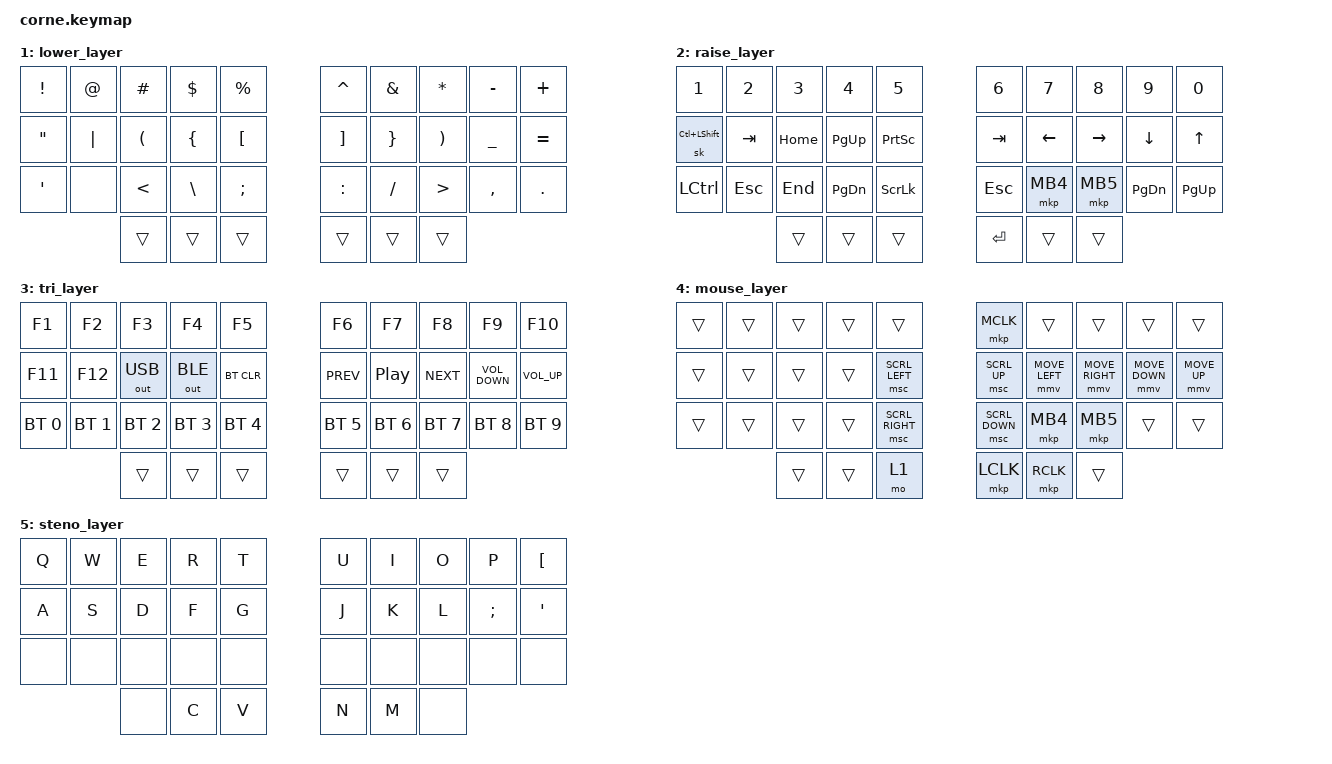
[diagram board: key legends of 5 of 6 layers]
/*
 * Copyright (c) 2020 The ZMK Contributors
 *
 * SPDX-License-Identifier: MIT
 */
#include <behaviors.dtsi> // I don't know what this does
#include <dt-bindings/zmk/keys.h> // This extends the options for the keymap bindings
#include <dt-bindings/zmk/outputs.h> //This allows you to toggle between Bluetooth and USB
#include <dt-bindings/zmk/bt.h> // This extends the functions of Bluetooth
#include <dt-bindings/zmk/mouse.h> // This enables mouse controls
#include <dt-bindings/zmk/pointing.h> // This also apparently activates "pointer device" control 

// Home row mods macro * This uses the HRM feature
#define HRML(k1, k2, k3, k4) &ht LALT k1  &ht LCTRL k2  &ht LGUI k3  &ht LSHFT k4
#define HRMR(k1, k2, k3, k4) &ht RSHFT k1  &ht RGUI k2  &ht RCTRL k3  &ht RALT k4
//Layers
        //Base Layer
        #define BASE 0 
        //Punctuation
        #define LOWER 1
        //Navigation
        #define RAISE 2
        // Bluetooth & Audio management 
        #define TRI 3
        // Mouse emulation
        #define MOUSE 4

#define ZMK_POINTING_DEFAULT_MOVE_VAL 1500  // default: 600 This changes the MAX mouse move velocities
#define ZMK_POINTING_DEFAULT_SCRL_VAL 20    // default: 10  This changes the MAX mouse move scroll

&mmv { // This controls the "base" movement speed & acceleration of "mouse move" function
    x-input-code = <INPUT_REL_X>;
    y-input-code = <INPUT_REL_Y>;
    time-to-max-speed-ms = <400>; // Default: 
    acceleration-exponent = <1>; // This is the exponent value for movement Default: 1 uniform speed 0, Uniform acceleration 1, linear acceleration 2
};
&msc { // This controls the "base" movement speed & acceleration of "Mouse Scroll" function
    x-input-code = <INPUT_REL_HWHEEL>;
    y-input-code = <INPUT_REL_WHEEL>;
    time-to-max-speed-ms = <300>;
    acceleration-exponent = <0>;
};

&mt {
};   

/ {
        chosen {
        zmk,matrix-transform = &five_column_transform;
        };
        conditional_layers { // This is a feature that allows you to make layers active as long as you hold them
            compatible = "zmk,conditional-layers";
            tri_layer {
                if-layers = <LOWER RAISE>;
                then-layer = <TRI>;
            };
        };  
       combos {// This allows key combinations perform other functions
            compatible = "zmk,combos";
                Combo_shift {
                        timeout-ms = <50>;
                        key-positions = <32 33>;
                        bindings = <&sk LSHFT>;
                        layers = < 0 1 >;
                };

        };
        behaviors {  
                ht: hold_tap {
                        label = "hold_tap";
                        compatible = "zmk,behavior-hold-tap";
                        #binding-cells = <2>;
                        flavor = "tap-preferred";
                        tapping-term-ms = <220>;
                        quick-tap-ms = <150>;
                        global-quick-tap;
                        bindings = <&kp>, <&kp>;
                };
                
                backspacenter: mod_del {
                        compatible = "zmk,behavior-mod-morph";
                        #binding-cells = <0>;
                        bindings = <&kp BSPC>, <&kp RET>;
                        mods = <(MOD_LSFT|MOD_RSFT)>;
                        keep-mods = <(MOD_LSFT)>;
                };
                spacedelete: grave_escape {
                        compatible = "zmk,behavior-mod-morph";
                        #binding-cells = <0>;
                        bindings = <&kp SPACE>, <&kp DEL>;
                        mods = <(MOD_LALT|MOD_RALT)>;
                        keep-mods = <(MOD_RALT)>;
                };

        };
        
        keymap {
                compatible = "zmk,keymap";
        default_layer {
                         bindings = <
                // ╭──────────┬──────────┬──────────┬──────────┬──────────╮       ╭──────────┬──────────┬──────────┬──────────┬──────────╮
                // |  Q       |  W       |  D       |  F       |  /       |       |  J       |  U       |  K       |  Y       |  '       |
                     &kp Q      &kp W      &kp D      &kp F      &kp FSLH           &kp J      &kp U      &kp K      &kp Y      &kp SQT
                // ├──────────┼──────────┼──────────┼──────────┼──────────┤       ├──────────┼──────────┼──────────┼──────────┼──────────┤
                // |  A, ALT  |  S, CTRL |  E, GUI  | T, SHIFT |  L       |       |  H       | N, SHIFT |  R, GUI  |  I, CTRL | O, ALT   |
                     HRML(A,    S,         E,         T)         &kp L              &kp H    HRMR(N,      R,         I,         O)   
                // ├──────────┼──────────┼──────────┼──────────┼──────────┤       ├──────────┼──────────┼──────────┼──────────┼──────────┤
                // |  G       |  X       |  C       |  V       |  Z       |       |  B       |  M       |  P       |  ,       |  .       |
                     &kp G      &kp X      &kp C      &kp V      &kp Z              &kp B      &kp M      &kp P      &kp COMMA  &kp DOT 
                // ╰──────────┴──────────┼──────────┼──────────┼──────────┤       ├──────────┴──────────┴──────────┼──────────┴──────────╯
                //                       |  Mouse   |          |          |       |          |          |          |
                                           &mo 4      &mo 2    &spacedelete      &backspacenter  &mo 1    &mo 2
                //                       ╰──────────┴──────────┴──────────╯       ╰──────────┴──────────┴──────────╯
                        >;
                };
        lower_layer {
                        bindings = <
                // ╭──────────┬──────────┬──────────┬──────────┬──────────╮       ╭──────────┬──────────┬──────────┬──────────┬──────────╮
                // |  !       |  @       |  #       |  $       |  %       |       |  ^       |  &       |  *       |  -       |  +       |
                     &kp EXCL   &kp AT     &kp HASH   &kp DLLR   &kp PRCNT          &kp CARET  &kp AMPS   &kp STAR   &kp MINUS  &kp PLUS   
                // ├──────────┼──────────┼──────────┼──────────┼──────────┤       ├──────────┼──────────┼──────────┼──────────┼──────────┤
                // |  "       |  "|"     |  (       | {        |  [       |       |  ]       |  }       |  )       |  _       |  =       |
                     &kp DQT    &kp PIPE   &kp LPAR  &kp LBRC   &kp LBKT            &kp RBKT   &kp RBRC   &kp RPAR   &kp UNDER  &kp EQUAL  
                // ├──────────┼──────────┼──────────┼──────────┼──────────┤       ├──────────┼──────────┼──────────┼──────────┼──────────┤
                // |  '       |          |  <       |  \       |  :       |       |  :       |  /       |  >       |  ,       |  .       |
                     &kp SQT    &none      &kp LT     &kp BSLH   &kp SEMI           &kp COLON  &kp FSLH   &kp GT     &kp COMMA  &kp DOT 
                // ╰──────────┴──────────┼──────────┼──────────┼──────────┤       ├──────────┴──────────┴──────────┼──────────┼──────────╯
                //                       |          |          |          |       |          |          |          |
                                            &trans     &trans     &trans             &trans     &trans     &trans
                //                       ╰──────────┴──────────┴──────────╯       ╰──────────┴──────────┴──────────╯
                        >;
                };
        raise_layer {
                        bindings = <
                // ╭──────────┬──────────┬──────────┬──────────┬──────────╮       ╭──────────┬──────────┬──────────┬──────────┬──────────╮
                // |  1       |  2       |  3       |  4       |  5       |       |  6       |  7       |  8       |  9       |  0       |
                      &kp N1     &kp N2     &kp N3     &kp N4     &kp N5             &kp N6     &kp N7     &kp N8     &kp N9     &kp N0 
                // ├──────────┼──────────┼──────────┼──────────┼──────────┤       ├──────────┼──────────┼──────────┼──────────┼──────────┤
                // | CTL+SHFT |  TAB     |  HOME    |  PGUP    | SCENSHOT |       |  TAB     |  left    |  right   |  DWN     |  UP      |
                &sk LC(LSHFT)   &kp TAB    &kp HOME   &kp PG_UP  &kp PSCRN          &kp TAB    &kp LEFT   &kp RIGHT  &kp DOWN   &kp UP  
                // ├──────────┼──────────┼──────────┼──────────┼──────────┤       ├──────────┼──────────┼──────────┼──────────┼──────────┤
                // |  CTRL    |  ESC     |  END     |  PGDN    |  SLCK    |       |  ESC     | Mouse 1  | Mouse 2  |PAGE DOWN | PAGE UP  |
                     &kp LCTRL  &kp ESC    &kp END    &kp PG_DN  &kp SLCK           &kp ESC    &mkp MB4   &mkp MB5 &kp PG_DN   &kp PG_UP  
                // ╰──────────┴──────────┼──────────┼──────────┼──────────┤       ├──────────┴──────────┴──────────┼──────────┴──────────╯
                //                       |          |          |          |       |  Enter   |          |          |
                                            &trans     &trans     &trans            &kp RET    &trans     &trans
                //                       ╰──────────┴──────────┴──────────╯       ╰──────────┴──────────┴──────────╯
                        >;
                };
                
        tri_layer {
                        bindings = < 
                // ╭──────────┬──────────┬──────────┬──────────┬──────────╮       ╭──────────┬──────────┬──────────┬──────────┬──────────╮
                // |  F1      |  F2      |  F3      |  F4      |  F5      |       |  F6      |  F7      |  F8      |  F9      |  F10     |
                     &kp F1     &kp F2     &kp F3     &kp F4     &kp F5              &kp F6    &kp F7     &kp F8     &kp F9     &kp F10  
                // ├──────────┼──────────┼──────────┼──────────┼──────────┤       ├──────────┼──────────┼──────────┼──────────┼──────────┤
                // |  F11     |  F12     | OUT USB  |  Out Bt  | BT Clear |       |   PREV   |   PLAY   |   NEXT   |   VO-    |   VO+    |
                     &kp F11    &kp F12  &out OUT_USB &out OUT_BLE &bt BT_CLR       &kp C_PREV &kp C_PP &kp C_NEXT &kp C_VOLUME_DOWN &kp C_VOL_UP 
                // ├──────────┼──────────┼──────────┼──────────┼──────────┤       ├──────────┼──────────┼──────────┼──────────┼──────────┤
                // | BT DEV 1 |BT DEV 2  | BT DEV 3 | BT DEV 4 | BT DEV 5 |       | BT DEV 6 | BT DEV 7 | BT DEV 8 | BT DEV 9 | BT DEV 10|
                &bt BT_SEL 0 &bt BT_SEL 1 &bt BT_SEL 2 &bt BT_SEL 3 &bt BT_SEL 4 &bt BT_SEL 5 &bt BT_SEL 6 &bt BT_SEL 7 &bt BT_SEL 8 &bt BT_SEL 9     
                // ╰──────────┴──────────┼──────────┼──────────┼──────────┤       ├──────────┴──────────┴──────────┼──────────┴──────────╯
                //                       |          |          |          |       |          |          |          |
                                           &trans     &trans     &trans             &trans     &trans     &trans
                //                       ╰──────────┴──────────┴──────────╯       ╰──────────┴──────────┴──────────╯
                        >;
                };
        mouse_layer { 
                        bindings = <
                // ╭──────────┬──────────┬──────────┬──────────┬──────────╮       ╭──────────┬──────────┬──────────┬──────────┬──────────╮
                // |          |          |          |          |          |       |  MIDDLE  |          |          |          |          |
                     &trans     &trans     &trans     &trans     &trans             &mkp MCLK  &trans     &trans     &trans     &trans
                // ├──────────┼──────────┼──────────┼──────────┼──────────┤       ├──────────┼──────────┼──────────┼──────────┼──────────┤
                // |  DOUBLE  |   HALF   |          |          |Scrl Left |       |Scrl UP   |  M Left  | M Right  | M Down   |  M Up    |
                     &trans     &trans    &trans      &trans     &msc SCRL_LEFT    &msc SCRL_UP &mmv MOVE_LEFT &mmv MOVE_RIGHT &mmv MOVE_DOWN &mmv MOVE_UP 
                // ├──────────┼──────────┼──────────┼──────────┼──────────┤       ├──────────┼──────────┼──────────┼──────────┼──────────┤
                // |          |          |          |          |Scrl Right|       |Scrl Down | Mouse 1  | Mouse 2  |          |          |
                     &trans     &trans     &trans     &trans     &msc SCRL_RIGHT  &msc SCRL_DOWN &mkp MB4 &mkp MB5   &trans     &trans 
                // ╰──────────┴──────────┼──────────┼──────────┼──────────┤       ├──────────┼──────────┼──────────┼──────────┴──────────╯
                //                       |          |          |  base    |       |Left Clk  |Right Clk |          |
                                           &trans     &trans     &mo 1            &mkp LCLK  &mkp RCLK     &trans 
                //                       ╰──────────┴──────────┴──────────╯       ╰──────────┴──────────┴──────────╯
                        >;
                };
        steno_layer {
                        bindings = <
                // ╭──────────┬──────────┬──────────┬──────────┬──────────╮       ╭──────────┬──────────┬──────────┬──────────┬──────────╮
                // |  Q, S    |  W, T    |  E, P    |  R, H    |  T, *    |       |  U, F    |  I, P    |  O, L    |  P, T    |  [, D    | 
                     &kp Q      &kp W      &kp E      &kp R      &kp T              &kp U      &kp I      &kp O      &kp P      &kp LBKT
                // ├──────────┼──────────┼──────────┼──────────┼──────────┤       ├──────────┼──────────┼──────────┼──────────┼──────────┤
                // |  A, S    |  S, K    |  D, W    |  F, R    |  G, *    |       |  J, R    |  K, B    |  L, G    |  ;, S    | ', Z     | 
                     &kp A      &kp S      &kp D      &kp F      &kp G              &kp J      &kp K      &kp L      &kp SEMI   &kp SQT 
                // ├──────────┼──────────┼──────────┼──────────┼──────────┤       ├──────────┼──────────┼──────────┼──────────┼──────────┤
                // |          |          |          |          |          |       |          |          |          |          |          |
                     &none      &none      &none      &none      &none              &none       &none     &none      &none      &none  
                // ╰──────────┴──────────┼──────────┼──────────┼──────────┤       ├──────────┼──────────┼──────────┼──────────┴──────────╯
                //                       |          |  C, A    |  V, O    |       |  N, E    |  M, U    |          |
                                           &none      &kp C     &kp V               &kp N      &kp M      &none 
                //                       ╰──────────┴──────────┴──────────╯       ╰──────────┴──────────┴──────────╯
                        >;
                };
        };
};
